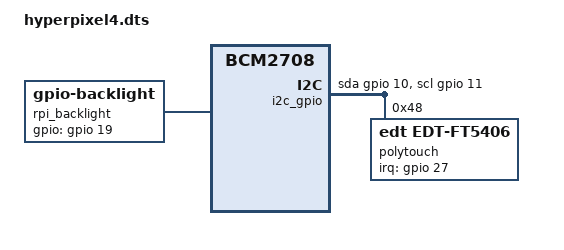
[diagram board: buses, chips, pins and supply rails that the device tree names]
/dts-v1/;
/plugin/;
/ {
	compatible = "brcm,bcm2708";
	fragment@0 {
		target = <0xdeadbeef>;
		__overlay__ {
			pinctrl-names = "default";
			pinctrl-0 = <0x1>;
		};
	};
	fragment@1 {
		target = <0xdeadbeef>;
		__overlay__ {
			dpi18_pins {
				brcm,pins = <0x0 0x1 0x2 0x3 0x4 0x5 0x6 0x7 0x8 0x9	0xc 0xd 0xe 0xf 0x10 0x11	 0x14 0x15 0x16 0x17 0x18 0x19>;
				brcm,function = <0x6>;
				brcm,pull = <0x0>;
				phandle = <0x1>;
			};
		};
	};
	fragment@2 {
                target = <&gpio>;
                __overlay__ {
                        edt_ft5x06_pins: edt_ft5x06_pins {
                                brcm,pins = <27>;
                                brcm,function = <0>;
                                brcm,pull = <2>;
                        };
                };
	};
	fragment@3 {
		target-path = "/";
		__overlay__ {
			i2c_gpio: i2c@0 {
				compatible = "i2c-gpio";
				gpios = <&gpio 10 0 /* sda */
					 &gpio 11 0 /* scl */
					>;
				i2c-gpio,delay-us = <1>;		/* ~100 kHz */
				#address-cells = <1>;
				#size-cells = <0>;
			};
		};
	};
	fragment@4 {
		target = <&i2c_gpio>;
                __overlay__ {
                        #address-cells = <1>;
                        #size-cells = <0>;
                        status = "okay";

                        polytouch: edt-ft5x06@48 {
                                #address-cells = <1>;
                                #size-cells = <0>;
                                compatible = "edt,edt-ft5406", "edt,edt-ft5x06";
                                reg = <0x48>;
                                pinctrl-names = "default";
                                pinctrl-0 = <&edt_ft5x06_pins>;
                                interrupt-parent = <&gpio>;
                                interrupts = <27 0x02>;
                                touchscreen-size-x = <720>;
                                touchscreen-size-y = <720>;
                        };
                };
	};
	fragment@5 {
		target-path = "/";
		__overlay__ {
			rpi_backlight: rpi_backlight {
				compatible = "gpio-backlight";
				gpios = <&gpio 19 0>;
				default-on;
			};
		};
	};
	fragment@6 {
		target = <&polytouch>;
		__overlay__ {
			touchscreen-inverted-x = <1>;
			touchscreen-inverted-y = <1>;
		};
	};
	__symbols__ {
		dpi18_pins = "/fragment@1/__overlay__/dpi18_pins";
	};
	__local_fixups__ {
		fragment@0 {
			__overlay__ {
				pinctrl-0 = <0x0>;
			};
		};
	};
	__fixups__ {
		leds = "/fragment@0:target:0";
		gpio = "/fragment@1:target:0";
	};
	__overrides__ {
		rotate = <0>,"-6";
	};
};

